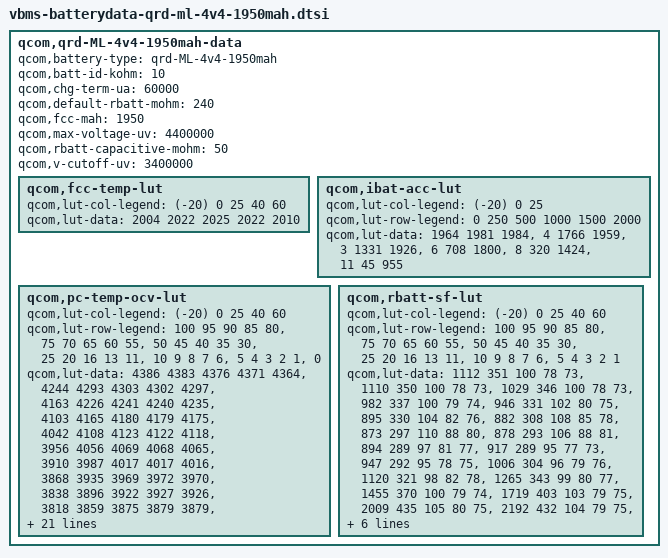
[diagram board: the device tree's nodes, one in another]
/* Copyright (c) 2018 The Linux Foundation. All rights reserved.
 *
 * This program is free software; you can redistribute it and/or modify
 * it under the terms of the GNU General Public License version 2 and
 * only version 2 as published by the Free Software Foundation.
 *
 * This program is distributed in the hope that it will be useful,
 * but WITHOUT ANY WARRANTY; without even the implied warranty of
 * MERCHANTABILITY or FITNESS FOR A PARTICULAR PURPOSE.  See the
 * GNU General Public License for more details.
 */

qcom,qrd-ML-4v4-1950mah-data {
	qcom,battery-type = "qrd-ML-4v4-1950mah";
	qcom,batt-id-kohm = <10>;
	qcom,chg-term-ua = <60000>;
	qcom,default-rbatt-mohm = <240>;
	qcom,fcc-mah = <1950>;
	qcom,max-voltage-uv = <4400000>;
	qcom,rbatt-capacitive-mohm = <50>;
	qcom,v-cutoff-uv = <3400000>;

	qcom,fcc-temp-lut {
		qcom,lut-col-legend = <(-20) 0 25 40 60>;
		qcom,lut-data = <2004 2022 2025 2022 2010>;
	};

	qcom,ibat-acc-lut {
		qcom,lut-col-legend = <(-20) 0 25>;
		qcom,lut-row-legend = <0 250 500 1000 1500 2000>;
		qcom,lut-data = <1964 1981 1984>,
				<4 1766 1959>,
				<3 1331 1926>,
				<6 708 1800>,
				<8 320 1424>,
				<11 45 955>;
	};

	qcom,pc-temp-ocv-lut {
		qcom,lut-col-legend = <(-20) 0 25 40 60>;
		qcom,lut-row-legend = <100 95 90 85 80>,
					<75 70 65 60 55>,
					<50 45 40 35 30>,
					<25 20 16 13 11>,
					<10 9 8 7 6>,
					<5 4 3 2 1>,
					<0>;
		qcom,lut-data = <4386 4383 4376 4371 4364>,
				<4244 4293 4303 4302 4297>,
				<4163 4226 4241 4240 4235>,
				<4103 4165 4180 4179 4175>,
				<4042 4108 4123 4122 4118>,
				<3956 4056 4069 4068 4065>,
				<3910 3987 4017 4017 4016>,
				<3868 3935 3969 3972 3970>,
				<3838 3896 3922 3927 3926>,
				<3818 3859 3875 3879 3879>,
				<3801 3828 3842 3843 3843>,
				<3786 3804 3817 3818 3818>,
				<3771 3788 3797 3799 3798>,
				<3755 3776 3781 3782 3781>,
				<3738 3764 3768 3766 3761>,
				<3719 3748 3755 3748 3735>,
				<3697 3729 3737 3729 3716>,
				<3676 3714 3716 3709 3695>,
				<3657 3701 3695 3688 3675>,
				<3642 3692 3686 3680 3669>,
				<3633 3688 3684 3679 3668>,
				<3620 3683 3683 3678 3667>,
				<3606 3676 3680 3676 3665>,
				<3590 3667 3676 3672 3662>,
				<3570 3652 3667 3661 3649>,
				<3547 3627 3639 3632 3616>,
				<3517 3590 3592 3584 3569>,
				<3478 3535 3529 3522 3507>,
				<3425 3452 3442 3438 3426>,
				<3346 3321 3310 3305 3305>,
				<3225 3118 3026 3000 3036>;
	};

	qcom,rbatt-sf-lut {
		qcom,lut-col-legend = <(-20) 0 25 40 60>;
		qcom,lut-row-legend = <100 95 90 85 80>,
					<75 70 65 60 55>,
					<50 45 40 35 30>,
					<25 20 16 13 11>,
					<10 9 8 7 6>,
					<5 4 3 2 1>;
		qcom,lut-data = <1112 351 100 78 73>,
				<1110 350 100 78 73>,
				<1029 346 100 78 73>,
				<982 337 100 79 74>,
				<946 331 102 80 75>,
				<895 330 104 82 76>,
				<882 308 108 85 78>,
				<873 297 110 88 80>,
				<878 293 106 88 81>,
				<894 289 97 81 77>,
				<917 289 95 77 73>,
				<947 292 95 78 75>,
				<1006 304 96 79 76>,
				<1120 321 98 82 78>,
				<1265 343 99 80 77>,
				<1455 370 100 79 74>,
				<1719 403 103 79 75>,
				<2009 435 105 80 75>,
				<2192 432 104 79 75>,
				<2382 460 105 79 74>,
				<2597 477 108 80 75>,
				<2847 498 111 82 76>,
				<3151 523 115 84 78>,
				<3531 552 120 87 79>,
				<4025 586 126 87 78>,
				<4699 631 127 86 77>,
				<5606 695 135 88 78>,
				<7035 877 151 93 80>,
				<9409 1337 183 104 88>,
				<13871 2674 262 130 99>;
	};
};
